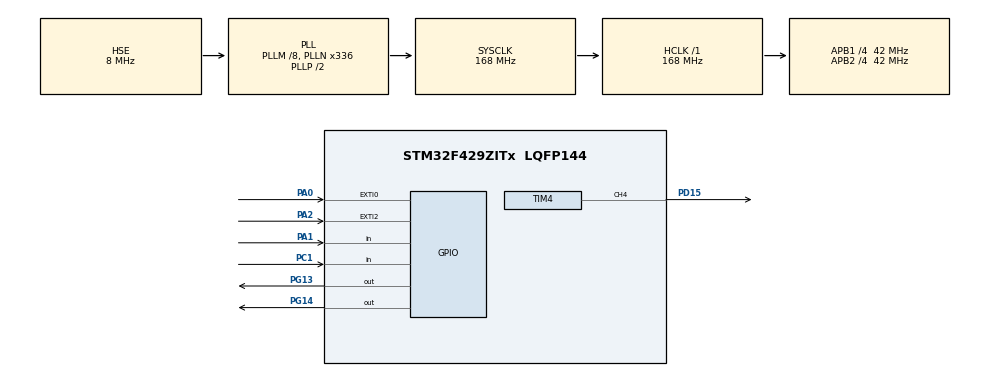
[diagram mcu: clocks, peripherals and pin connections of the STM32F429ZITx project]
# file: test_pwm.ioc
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Mcu.Family=STM32F4
Mcu.Name=STM32F429ZITx
Mcu.Package=LQFP144
NVIC.EXTI0_IRQn=true\:0\:0\:false\:false\:true\:true\:true
NVIC.PriorityGroup=NVIC_PRIORITYGROUP_4
PA0/WKUP.GPIO_ModeDefaultEXTI=GPIO_MODE_IT_RISING_FALLING
PA0/WKUP.Signal=GPXTI0
PA1.GPIO_PuPd=GPIO_NOPULL
PA1.Signal=GPIO_Input
PA2.GPIO_ModeDefaultEXTI=GPIO_MODE_IT_RISING_FALLING
PA2.Signal=GPXTI2
PC1.Signal=GPIO_Input
PD15.Signal=S_TIM4_CH4
PG13.Signal=GPIO_Output
PG14.Signal=GPIO_Output
PH0/OSC_IN.Mode=HSE-External-Oscillator
PH0/OSC_IN.Signal=RCC_OSC_IN
PH1/OSC_OUT.Mode=HSE-External-Oscillator
PH1/OSC_OUT.Signal=RCC_OSC_OUT
ProjectManager.HeapSize=0x200
ProjectManager.StackSize=0x400
ProjectManager.TargetToolchain=MDK-ARM V5
RCC.48MHZClocksFreq_Value=84000000
RCC.AHBFreq_Value=168000000
RCC.APB1CLKDivider=RCC_HCLK_DIV4
RCC.APB1Freq_Value=42000000
RCC.APB1TimFreq_Value=84000000
RCC.APB2CLKDivider=RCC_HCLK_DIV4
RCC.APB2Freq_Value=42000000
RCC.APB2TimFreq_Value=84000000
RCC.CortexFreq_Value=168000000
RCC.HCLKFreq_Value=168000000
RCC.HSE_VALUE=8000000
RCC.HSI_VALUE=16000000
RCC.LSE_VALUE=32768
RCC.PLLM=8
RCC.PLLN=336
RCC.PLLSourceVirtual=RCC_PLLSOURCE_HSE
RCC.SYSCLKFreq_VALUE=168000000
RCC.SYSCLKSource=RCC_SYSCLKSOURCE_PLLCLK
RCC.VCOOutputFreq_Value=336000000
SH.S_TIM4_CH4.0=TIM4_CH4,PWM Generation4 CH4
TIM4.Channel-PWM\ Generation4\ CH4=TIM_CHANNEL_4
TIM4.Period=400
TIM4.Prescaler=4200
VP_TIM4_VS_ClockSourceINT.Mode=Internal
board=custom

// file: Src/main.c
/* USER CODE BEGIN Header */
/**
  ******************************************************************************
  * @file           : main.c
  * @brief          : Main program body
  ******************************************************************************
  * @attention
  *
  * <h2><center>&copy; Copyright (c) 2020 STMicroelectronics.
  * All rights reserved.</center></h2>
  *
  * This software component is licensed by ST under BSD 3-Clause license,
  * the "License"; You may not use this file except in compliance with the
  * License. You may obtain a copy of the License at:
  *                        opensource.org/licenses/BSD-3-Clause
  *
  ******************************************************************************
  */
/* USER CODE END Header */

#include "main.h"

TIM_HandleTypeDef htim4;

/* USER CODE BEGIN PV */
uint16_t duty=0,data1,data2;
int count_value=0;
/* USER CODE END PV */

void SystemClock_Config(void);
static void MX_GPIO_Init(void);
static void MX_TIM4_Init(void);

int main(void)
{

  /* MCU Configuration--------------------------------------------------------*/

  /* Reset of all peripherals, Initializes the Flash interface and the Systick. */
  HAL_Init();

  /* Configure the system clock */
  SystemClock_Config();

  /* Initialize all configured peripherals */
  MX_GPIO_Init();
  MX_TIM4_Init();
  /* USER CODE BEGIN 2 */
//		HAL_TIM_Base_Start_IT(&htim2);
	HAL_TIM_PWM_Start(&htim4,TIM_CHANNEL_4);

  /* USER CODE END 2 */

  /* Infinite loop */
  /* USER CODE BEGIN WHILE */
  while (1)
  {
		__HAL_TIM_SET_COMPARE(&htim4,TIM_CHANNEL_4,duty);
//		count_value=__HAL_TIM_GET_COUNTER(&htim2);
		HAL_Delay(200);
//		data2=HAL_GPIO_ReadPin(GPIOA, GPIO_PIN_2);
    /* USER CODE END WHILE */

  }
}

void SystemClock_Config(void)
{
  RCC_OscInitTypeDef RCC_OscInitStruct = {0};
  RCC_ClkInitTypeDef RCC_ClkInitStruct = {0};

  /** Configure the main internal regulator output voltage
  */
  __HAL_RCC_PWR_CLK_ENABLE();
  __HAL_PWR_VOLTAGESCALING_CONFIG(PWR_REGULATOR_VOLTAGE_SCALE1);
  /** Initializes the CPU, AHB and APB busses clocks
  */
  RCC_OscInitStruct.OscillatorType = RCC_OSCILLATORTYPE_HSE;
  RCC_OscInitStruct.HSEState = RCC_HSE_ON;
  RCC_OscInitStruct.PLL.PLLState = RCC_PLL_ON;
  RCC_OscInitStruct.PLL.PLLSource = RCC_PLLSOURCE_HSE;
  RCC_OscInitStruct.PLL.PLLM = 8;
  RCC_OscInitStruct.PLL.PLLN = 336;
  RCC_OscInitStruct.PLL.PLLP = RCC_PLLP_DIV2;
  RCC_OscInitStruct.PLL.PLLQ = 4;
  if (HAL_RCC_OscConfig(&RCC_OscInitStruct) != HAL_OK)
  {
    Error_Handler();
  }
  /** Initializes the CPU, AHB and APB busses clocks
  */
  RCC_ClkInitStruct.ClockType = RCC_CLOCKTYPE_HCLK|RCC_CLOCKTYPE_SYSCLK
                              |RCC_CLOCKTYPE_PCLK1|RCC_CLOCKTYPE_PCLK2;
  RCC_ClkInitStruct.SYSCLKSource = RCC_SYSCLKSOURCE_PLLCLK;
  RCC_ClkInitStruct.AHBCLKDivider = RCC_SYSCLK_DIV1;
  RCC_ClkInitStruct.APB1CLKDivider = RCC_HCLK_DIV4;
  RCC_ClkInitStruct.APB2CLKDivider = RCC_HCLK_DIV4;

  if (HAL_RCC_ClockConfig(&RCC_ClkInitStruct, FLASH_LATENCY_5) != HAL_OK)
  {
    Error_Handler();
  }
}

static void MX_TIM4_Init(void)
{

  TIM_ClockConfigTypeDef sClockSourceConfig = {0};
  TIM_MasterConfigTypeDef sMasterConfig = {0};
  TIM_OC_InitTypeDef sConfigOC = {0};

  htim4.Instance = TIM4;
  htim4.Init.Prescaler = 4200;
  htim4.Init.CounterMode = TIM_COUNTERMODE_UP;
  htim4.Init.Period = 400;
  htim4.Init.ClockDivision = TIM_CLOCKDIVISION_DIV1;
  htim4.Init.AutoReloadPreload = TIM_AUTORELOAD_PRELOAD_DISABLE;
  if (HAL_TIM_Base_Init(&htim4) != HAL_OK)
  {
    Error_Handler();
  }
  sClockSourceConfig.ClockSource = TIM_CLOCKSOURCE_INTERNAL;
  if (HAL_TIM_ConfigClockSource(&htim4, &sClockSourceConfig) != HAL_OK)
  {
    Error_Handler();
  }
  if (HAL_TIM_PWM_Init(&htim4) != HAL_OK)
  {
    Error_Handler();
  }
  sMasterConfig.MasterOutputTrigger = TIM_TRGO_RESET;
  sMasterConfig.MasterSlaveMode = TIM_MASTERSLAVEMODE_DISABLE;
  if (HAL_TIMEx_MasterConfigSynchronization(&htim4, &sMasterConfig) != HAL_OK)
  {
    Error_Handler();
  }
  sConfigOC.OCMode = TIM_OCMODE_PWM1;
  sConfigOC.Pulse = 0;
  sConfigOC.OCPolarity = TIM_OCPOLARITY_HIGH;
  sConfigOC.OCFastMode = TIM_OCFAST_DISABLE;
  if (HAL_TIM_PWM_ConfigChannel(&htim4, &sConfigOC, TIM_CHANNEL_4) != HAL_OK)
  {
    Error_Handler();
  }
  HAL_TIM_MspPostInit(&htim4);

}

static void MX_GPIO_Init(void)
{
  GPIO_InitTypeDef GPIO_InitStruct = {0};

  /* GPIO Ports Clock Enable */
  __HAL_RCC_GPIOH_CLK_ENABLE();
  __HAL_RCC_GPIOC_CLK_ENABLE();
  __HAL_RCC_GPIOA_CLK_ENABLE();
  __HAL_RCC_GPIOD_CLK_ENABLE();
  __HAL_RCC_GPIOG_CLK_ENABLE();

  /*Configure GPIO pin Output Level */
  HAL_GPIO_WritePin(GPIOG, GPIO_PIN_13|GPIO_PIN_14, GPIO_PIN_RESET);

  /*Configure GPIO pin : PC1 */
  GPIO_InitStruct.Pin = GPIO_PIN_1;
  GPIO_InitStruct.Mode = GPIO_MODE_INPUT;
  GPIO_InitStruct.Pull = GPIO_NOPULL;
  HAL_GPIO_Init(GPIOC, &GPIO_InitStruct);

  /*Configure GPIO pins : PA0 PA2 */
  GPIO_InitStruct.Pin = GPIO_PIN_0|GPIO_PIN_2;
  GPIO_InitStruct.Mode = GPIO_MODE_IT_RISING_FALLING;
  GPIO_InitStruct.Pull = GPIO_NOPULL;
  HAL_GPIO_Init(GPIOA, &GPIO_InitStruct);

  /*Configure GPIO pin : PA1 */
  GPIO_InitStruct.Pin = GPIO_PIN_1;
  GPIO_InitStruct.Mode = GPIO_MODE_INPUT;
  GPIO_InitStruct.Pull = GPIO_NOPULL;
  HAL_GPIO_Init(GPIOA, &GPIO_InitStruct);

  /*Configure GPIO pins : PG13 PG14 */
  GPIO_InitStruct.Pin = GPIO_PIN_13|GPIO_PIN_14;
  GPIO_InitStruct.Mode = GPIO_MODE_OUTPUT_PP;
  GPIO_InitStruct.Pull = GPIO_NOPULL;
  GPIO_InitStruct.Speed = GPIO_SPEED_FREQ_LOW;
  HAL_GPIO_Init(GPIOG, &GPIO_InitStruct);

  /* EXTI interrupt init*/
  HAL_NVIC_SetPriority(EXTI0_IRQn, 0, 0);
  HAL_NVIC_EnableIRQ(EXTI0_IRQn);

}

/* USER CODE BEGIN 4 */
//void HAL_GPIO_EXTI_Callback(uint16_t GPIO_Pin)
//{
//	 count_value++;
//	HAL_GPIO_TogglePin(GPIOG,GPIO_PIN_13);
////	data1=HAL_GPIO_ReadPin(GPIOA, GPIO_PIN_0);
////	data2=HAL_GPIO_ReadPin(GPIOC, GPIO_PIN_1);
//	if(HAL_GPIO_ReadPin(GPIOA, GPIO_PIN_0)==HAL_GPIO_ReadPin(GPIOC, GPIO_PIN_1))
//	{
//		data1=1;
//	}else data1=2;
//
//}
void HAL_TIM_PeriodElapsedCallback(TIM_HandleTypeDef *htim)
{

//	if(htim->Instance==htim2.Instance)
//		{
//			HAL_GPIO_TogglePin(GPIOG,GPIO_PIN_13);
//			HAL_GPIO_ReadPin(GPIOA, GPIO_PIN_1);
//
//		}

//	if(htim->Instance==htim5.Instance)
//		{
//			flag2++;
//			HAL_GPIO_TogglePin(GPIOG,GPIO_PIN_13);
//		}
}

/* USER CODE END 4 */

void Error_Handler(void)
{
}

/************************ (C) COPYRIGHT STMicroelectronics *****END OF FILE****/
